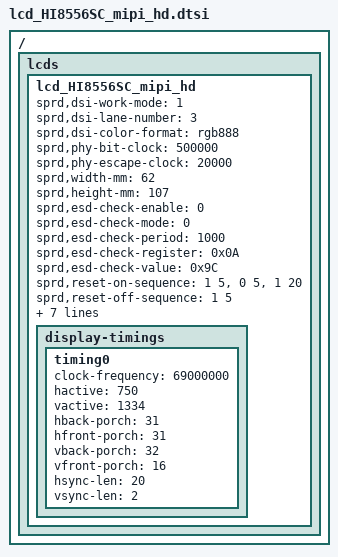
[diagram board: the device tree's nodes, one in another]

/*
 * R61350 Truly LCD config dtsi file for spreadtrum
 *
 * Copyright (C) 2018, Spreadtrum Communications Inc.
 *
 * SPDX-License-Identifier: (GPL-2.0+ OR MIT)
 */

/ { lcds {
	lcd_HI8556SC_mipi_hd: lcd_HI8556SC_mipi_hd {

		sprd,dsi-work-mode = <1>; /* video burst mode*/
		sprd,dsi-lane-number = <3>;
		sprd,dsi-color-format = "rgb888";

		sprd,phy-bit-clock = <500000>;	/* kbps */
		sprd,phy-escape-clock = <20000>;/* kHz */

		sprd,width-mm = <62>;
		sprd,height-mm = <107>;

		sprd,esd-check-enable = <0>;
		sprd,esd-check-mode = <0>;
		sprd,esd-check-period = <1000>;
		sprd,esd-check-register = <0x0A>;
		sprd,esd-check-value = <0x9C>;

		sprd,reset-on-sequence = <1 5>, <0 5>, <1 20>;
		sprd,reset-off-sequence = <1 5>;

		sprd,use-dcs-write;
		sprd,initial-command = [
	
			05 78 00 01 11
			05 32 00 01 29
			];

		sprd,sleep-in-command = [
			15 32 00 01 28
			15 96 00 01 10
			29 00 00 02 B0 00
			29 14 00 02 B1 01
			];

		sprd,sleep-out-command = [
			15 78 00 01 11
			15 32 00 01 29
			15 01 00 02 B0 00
			15 01 00 02 B1 01
			];

		display-timings {
			timing0 {
				clock-frequency = <69000000>;
				hactive = <750>;
				vactive = <1334>;
				hback-porch = <31>;
				hfront-porch = <31>;
				vback-porch = <32>;
				vfront-porch = <16>;
				hsync-len = <20>;
				vsync-len = <2>;
			};
		};
	};
};};
